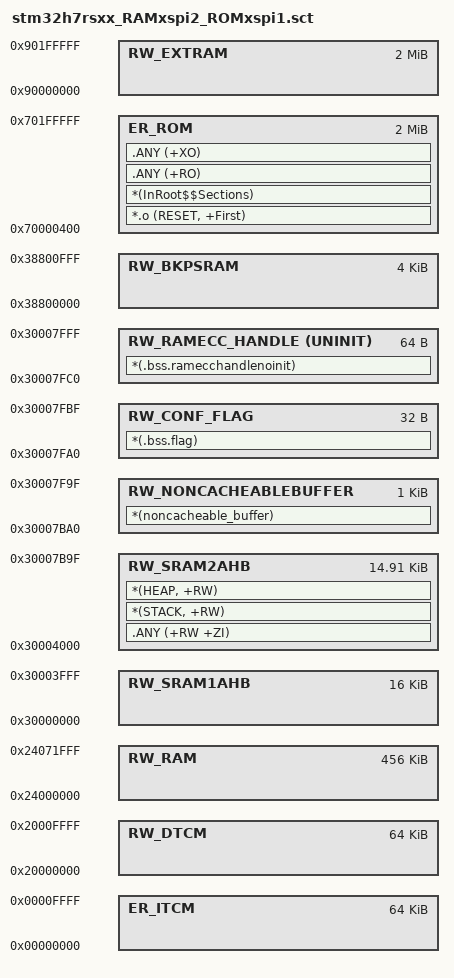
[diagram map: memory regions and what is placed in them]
#! armclang --target=arm-arm-none-eabi -march=armv7-m -E -xc

; *************************************************************
; *** Scatter-Loading Description File generated by uVision ***
; *************************************************************

#define CODE_OFFSET       0x0        /* This define is updated automatically from OEMiROT_BOOT project */
#define CODE_SIZE         0x200000   /* This define is updated automatically from OEMiROT_BOOT project */
#define PARTITION_START   0x70000000 /* This define is updated automatically from OEMiROT_BOOT project */
#define IMAGE_HEADER_SIZE 0x400      /* mcuboot header size */

/*-Memory Regions-*/
#define ROM_START                PARTITION_START + CODE_OFFSET + IMAGE_HEADER_SIZE
#define ROM_SIZE                 CODE_SIZE - IMAGE_HEADER_SIZE

#define NONCACHEABLEBUFFER_START 0x30007BA0 /* End: 0x30007F9F */
#define NONCACHEABLEBUFFER_SIZE  0x400

#define CONF_FLAG_START          0x30007FA0 /* End: 0x30007FBF */
#define CONF_FLAG_SIZE           0x20

#define RAMECC_HANDLE_START     0x30007FC0 /* End: 0x30007FFF */
#define RAMECC_HANDLE_SIZE      0x40

#define RAM_SIZE                 0x4000 - NONCACHEABLEBUFFER_SIZE - CONF_FLAG_SIZE - RAMECC_HANDLE_SIZE

LOAD_FLASH ROM_START ROM_SIZE  {    ; load region size_region
  ER_ROM ROM_START ROM_SIZE  {  ; load address = execution address
   *.o (RESET, +First)
   *(InRoot$$Sections)
   .ANY (+RO)
   .ANY (+XO)
  }

  ER_ITCM 0x00000000 0x00010000  {  ;
  }

  RW_DTCM 0x20000000 0x00010000  {
  }

;  RW_SRAMAHB 0x30000000 0x8000  {
;  }

  RW_SRAM1AHB 0x30000000 0x4000  {
  }

  RW_SRAM2AHB 0x30004000 RAM_SIZE  {  ; RW data
   .ANY (+RW +ZI)
   *(STACK, +RW)
   *(HEAP, +RW)
  }

  RW_CONF_FLAG CONF_FLAG_START CONF_FLAG_SIZE {
   *(.bss.flag)
  }

  RW_RAMECC_HANDLE RAMECC_HANDLE_START UNINIT RAMECC_HANDLE_SIZE {
   *(.bss.ramecchandlenoinit)
  }

  RW_BKPSRAM 0x38800000 0x1000  {
  }

  RW_EXTRAM 0x90000000 0x200000  {
  }

  RW_RAM 0x24000000  0x00072000  {
  }

  RW_NONCACHEABLEBUFFER  NONCACHEABLEBUFFER_START NONCACHEABLEBUFFER_SIZE  {
   *(noncacheable_buffer)
  }
}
